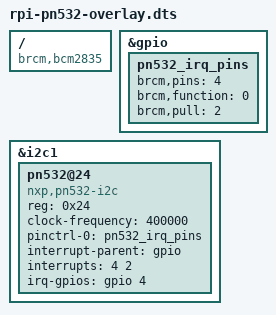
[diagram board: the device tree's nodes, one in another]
// pn532 nfc
/dts-v1/;
/plugin/;

/ {
        compatible = "brcm,bcm2835";
        fragment@0 {
                target = <&gpio>;
                __overlay__ {
                        pn532_irq_pins: pn532_irq_pins {
                                brcm,pins = <4>; // interrupt and reset
                                brcm,function = <0>; // in
                                brcm,pull = <2>; // pull-up
                        };
                };
        };


        fragment@1 {
                target = <&i2c1>;
                __overlay__ {
                        #address-cells = <1>;
                        #size-cells = <0>;
                        status = "okay";

                        pn532@24 {
				compatible = "nxp,pn532-i2c";

				reg = <0x24>;
				clock-frequency = <400000>;

				pinctrl-names = "default";
				pinctrl-0 = <&pn532_irq_pins>;

				interrupt-parent = <&gpio>;
				interrupts = <4 2>;
				irq-gpios = <&gpio 4 0>;

                                status = "okay";
                        };
                };
        };
};
